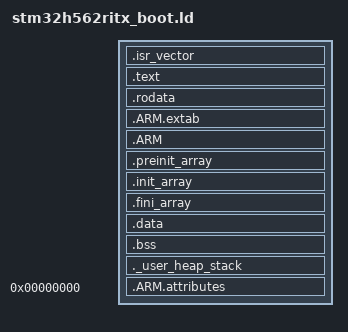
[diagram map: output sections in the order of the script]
INCLUDE stm32h562ritx/stm32h562ritx_memory.ld

/* Entry Point */
ENTRY(Reset_Handler)

/* Highest address of the user mode stack */
_estack = ORIGIN(ram) + LENGTH(ram);    /* end of RAM */

/* Generate a link error if heap and stack don't fit into RAM */
_Min_Heap_Size = 0x0;      /* required amount of heap  */
_Min_Stack_Size = 0x400;   /* required amount of stack */

/* Define output sections */
SECTIONS
{
  /* The startup code goes first into boot_code */
  .isr_vector :
  {
    . = ALIGN(4);
    KEEP(*(.isr_vector)) /* Startup code */
    . = ALIGN(4);
  } >boot_code

  .text :
  {
    . = ALIGN(4);
    *(.text)
    *(.text*)
    *(.glue_7)
    *(.glue_7t)
    *(.eh_frame)

    KEEP (*(.init))
    KEEP (*(.fini))

    . = ALIGN(4);
    _etext = .;
  } >boot_code

  .rodata :
  {
    . = ALIGN(4);
    *(.rodata)
    *(.rodata*)
    . = ALIGN(4);
  } >boot_code

  .ARM.extab : { *(.ARM.extab* .gnu.linkonce.armextab.*) } >boot_code
  .ARM :
  {
    __exidx_start = .;
    *(.ARM.exidx*)
    __exidx_end = .;
  } >boot_code

  .preinit_array :
  {
    PROVIDE_HIDDEN (__preinit_array_start = .);
    KEEP (*(.preinit_array*))
    PROVIDE_HIDDEN (__preinit_array_end = .);
  } >boot_code

  .init_array :
  {
    PROVIDE_HIDDEN (__init_array_start = .);
    KEEP (*(SORT(.init_array.*)))
    KEEP (*(.init_array*))
    PROVIDE_HIDDEN (__init_array_end = .);
  } >boot_code

  .fini_array :
  {
    PROVIDE_HIDDEN (__fini_array_start = .);
    KEEP (*(SORT(.fini_array.*)))
    KEEP (*(.fini_array*))
    PROVIDE_HIDDEN (__fini_array_end = .);
  } >boot_code

  /* Automatically computed FLASH end for .data load address */
  _boot_code_end = .;
  _sidata = _boot_code_end;

  /* Initialized data section: LMA in FLASH, VMA in RAM */
  .data : AT(_boot_code_end)
  {
    . = ALIGN(4);
    _sdata = .;
    *(.data)
    *(.data*)
    *(.RamFunc)
    *(.RamFunc*)
    . = ALIGN(4);
    _edata = .;
  } >ram

  .bss :
  {
    . = ALIGN(4);
    _sbss = .;
    __bss_start__ = _sbss;
    *(.bss)
    *(.bss*)
    *(COMMON)
    . = ALIGN(4);
    _ebss = .;
    __bss_end__ = _ebss;
  } >ram

  ._user_heap_stack :
  {
    . = ALIGN(8);
    PROVIDE (end = .);
    PROVIDE (_end = .);
    . = . + _Min_Heap_Size;
    . = . + _Min_Stack_Size;
    . = ALIGN(8);
  } >ram

  /DISCARD/ :
  {
    libc.a ( * )
    libm.a ( * )
    libgcc.a ( * )
  }

  .ARM.attributes 0 : { *(.ARM.attributes) }
}
